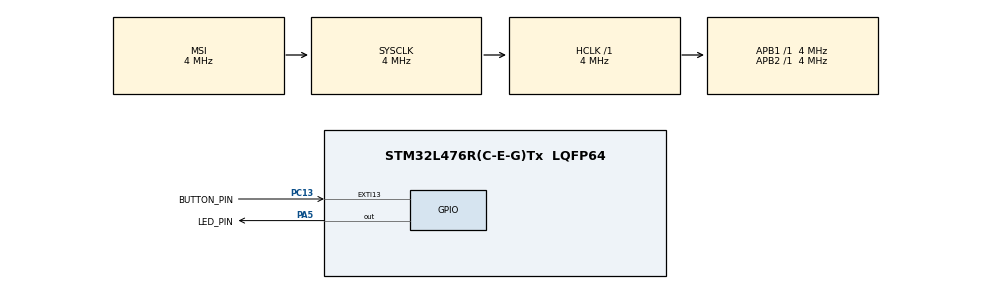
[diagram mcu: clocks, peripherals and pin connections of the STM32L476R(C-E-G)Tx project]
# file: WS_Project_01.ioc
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Mcu.Family=STM32L4
Mcu.Name=STM32L476R(C-E-G)Tx
Mcu.Package=LQFP64
NVIC.EXTI15_10_IRQn=true\:0\:0\:false\:false\:true\:true\:true\:true
NVIC.PriorityGroup=NVIC_PRIORITYGROUP_4
PA5.GPIO_Label=LED_PIN
PA5.Signal=GPIO_Output
PC13.GPIO_Label=BUTTON_PIN
PC13.GPIO_PuPd=GPIO_PULLUP
PC13.Signal=GPXTI13
ProjectManager.HeapSize=0x200
ProjectManager.StackSize=0x400
ProjectManager.TargetToolchain=STM32CubeIDE
RCC.ADCFreq_Value=16000000
RCC.AHBFreq_Value=4000000
RCC.APB1Freq_Value=4000000
RCC.APB1TimFreq_Value=4000000
RCC.APB2Freq_Value=4000000
RCC.APB2TimFreq_Value=4000000
RCC.CortexFreq_Value=4000000
RCC.HCLKFreq_Value=4000000
RCC.HSE_VALUE=8000000
RCC.HSI_VALUE=16000000
RCC.LSE_VALUE=32768
RCC.MSI_VALUE=4000000
RCC.SYSCLKFreq_VALUE=4000000
RCC.USBFreq_Value=16000000
RCC.VCOOutputFreq_Value=32000000
board=custom

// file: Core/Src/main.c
/* USER CODE BEGIN Header */
/**
  ******************************************************************************
  * @file           : main.c
  * @brief          : Main program body
  ******************************************************************************
  * @attention
  *
  * Copyright (c) 2026 STMicroelectronics.
  * All rights reserved.
  *
  * This software is licensed under terms that can be found in the LICENSE file
  * in the root directory of this software component.
  * If no LICENSE file comes with this software, it is provided AS-IS.
  *
  ******************************************************************************
  */
/* USER CODE END Header */
#include "main.h"

/* USER CODE BEGIN PD */
#define DEBOUNCE_TIME_MS    50
#define LONG_PRESS_TIME_MS  2000
/* USER CODE END PD */

/* USER CODE BEGIN PV */
volatile uint32_t pressTime = 0;
volatile uint32_t lastInterruptTime = 0;
volatile uint8_t buttonPressed = 0;
volatile uint8_t longPressEvent = 0;
volatile uint8_t shortPressEvent = 0;
/* USER CODE END PV */

void SystemClock_Config(void);
static void MX_GPIO_Init(void);

/* USER CODE BEGIN 0 */
void HAL_GPIO_EXTI_Callback(uint16_t GPIO_Pin)
{
    if(GPIO_Pin != GPIO_PIN_13)
        return;

    uint32_t currentTime = HAL_GetTick();

    /* Software debounce */
    if((currentTime - lastInterruptTime) < DEBOUNCE_TIME_MS)
        return;

    lastInterruptTime = currentTime;

    /* Button Pressed */
    if(HAL_GPIO_ReadPin(GPIOC, GPIO_PIN_13) == GPIO_PIN_RESET)
    {
        pressTime = currentTime;
        buttonPressed = 1;
    }
    else
    {
        /* Button Released */

        if(buttonPressed)
        {
            uint32_t pressDuration =
                currentTime - pressTime;

            if(pressDuration >= LONG_PRESS_TIME_MS)
                longPressEvent = 1;
            else
                shortPressEvent = 1;

            buttonPressed = 0;
        }
    }
}

void Blink_LED_3_Times(void)
{
    for(int i = 0; i < 3; i++)
    {
        HAL_GPIO_TogglePin(GPIOA,
                           GPIO_PIN_5);

        HAL_Delay(150);

        HAL_GPIO_TogglePin(GPIOA,
                           GPIO_PIN_5);

        HAL_Delay(150);
    }
}
/* USER CODE END 0 */

int main(void)
{

  /* MCU Configuration--------------------------------------------------------*/

  /* Reset of all peripherals, Initializes the Flash interface and the Systick. */
  HAL_Init();

  /* Configure the system clock */
  SystemClock_Config();

  /* Initialize all configured peripherals */
  MX_GPIO_Init();

  /* Infinite loop */
  while (1)
  {

    /* USER CODE BEGIN 3 */
	    if(shortPressEvent)
	    {
	        shortPressEvent = 0;
	        HAL_GPIO_TogglePin(GPIOA, GPIO_PIN_5);
	    }

	    if(longPressEvent)
	    {
	        longPressEvent = 0;
	        Blink_LED_3_Times();
	    }
  }
  /* USER CODE END 3 */
}

void SystemClock_Config(void)
{
  RCC_OscInitTypeDef RCC_OscInitStruct = {0};
  RCC_ClkInitTypeDef RCC_ClkInitStruct = {0};

  /** Configure the main internal regulator output voltage
  */
  if (HAL_PWREx_ControlVoltageScaling(PWR_REGULATOR_VOLTAGE_SCALE1) != HAL_OK)
  {
    Error_Handler();
  }

  /** Initializes the RCC Oscillators according to the specified parameters
  * in the RCC_OscInitTypeDef structure.
  */
  RCC_OscInitStruct.OscillatorType = RCC_OSCILLATORTYPE_MSI;
  RCC_OscInitStruct.MSIState = RCC_MSI_ON;
  RCC_OscInitStruct.MSICalibrationValue = 0;
  RCC_OscInitStruct.MSIClockRange = RCC_MSIRANGE_6;
  RCC_OscInitStruct.PLL.PLLState = RCC_PLL_NONE;
  if (HAL_RCC_OscConfig(&RCC_OscInitStruct) != HAL_OK)
  {
    Error_Handler();
  }

  /** Initializes the CPU, AHB and APB buses clocks
  */
  RCC_ClkInitStruct.ClockType = RCC_CLOCKTYPE_HCLK|RCC_CLOCKTYPE_SYSCLK
                              |RCC_CLOCKTYPE_PCLK1|RCC_CLOCKTYPE_PCLK2;
  RCC_ClkInitStruct.SYSCLKSource = RCC_SYSCLKSOURCE_MSI;
  RCC_ClkInitStruct.AHBCLKDivider = RCC_SYSCLK_DIV1;
  RCC_ClkInitStruct.APB1CLKDivider = RCC_HCLK_DIV1;
  RCC_ClkInitStruct.APB2CLKDivider = RCC_HCLK_DIV1;

  if (HAL_RCC_ClockConfig(&RCC_ClkInitStruct, FLASH_LATENCY_0) != HAL_OK)
  {
    Error_Handler();
  }
}

static void MX_GPIO_Init(void)
{
  GPIO_InitTypeDef GPIO_InitStruct = {0};

  /* GPIO Ports Clock Enable */
  __HAL_RCC_GPIOC_CLK_ENABLE();
  __HAL_RCC_GPIOA_CLK_ENABLE();

  /*Configure GPIO pin Output Level */
  HAL_GPIO_WritePin(LED_PIN_GPIO_Port, LED_PIN_Pin, GPIO_PIN_RESET);

  /*Configure GPIO pin : BUTTON_PIN_Pin */
  GPIO_InitStruct.Pin = BUTTON_PIN_Pin;
  GPIO_InitStruct.Mode = GPIO_MODE_IT_RISING_FALLING;
  GPIO_InitStruct.Pull = GPIO_PULLUP;
  HAL_GPIO_Init(BUTTON_PIN_GPIO_Port, &GPIO_InitStruct);

  /*Configure GPIO pin : LED_PIN_Pin */
  GPIO_InitStruct.Pin = LED_PIN_Pin;
  GPIO_InitStruct.Mode = GPIO_MODE_OUTPUT_PP;
  GPIO_InitStruct.Pull = GPIO_NOPULL;
  GPIO_InitStruct.Speed = GPIO_SPEED_FREQ_LOW;
  HAL_GPIO_Init(LED_PIN_GPIO_Port, &GPIO_InitStruct);

  /* EXTI interrupt init*/
  HAL_NVIC_SetPriority(EXTI15_10_IRQn, 0, 0);
  HAL_NVIC_EnableIRQ(EXTI15_10_IRQn);

}

void Error_Handler(void)
{
  __disable_irq();
  while (1)
  {
  }
}
